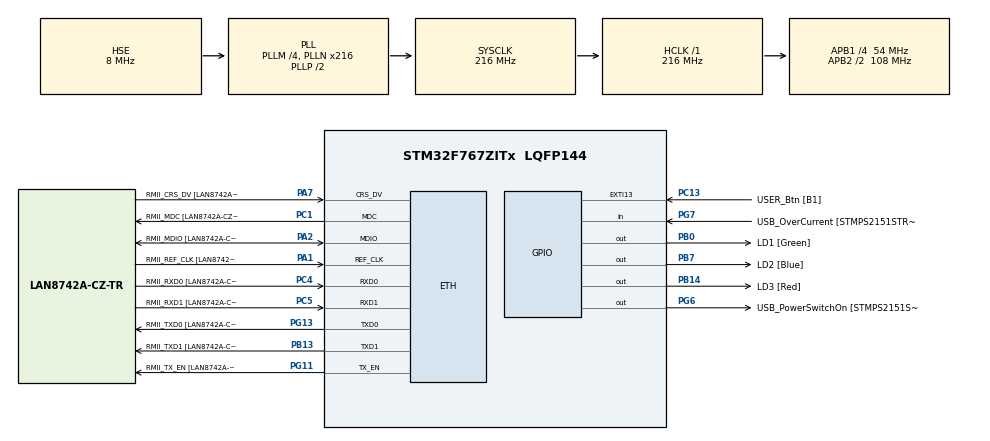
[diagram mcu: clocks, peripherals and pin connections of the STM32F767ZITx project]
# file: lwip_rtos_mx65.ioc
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ETH.MediaInterface=ETH_MEDIA_INTERFACE_RMII
ETH.PHY_Name=LAN8742A_PHY_ADDRESS
ETH.PHY_Value=0
ETH.PhyAddress=0
FREERTOS.Tasks01=defaultTask,24,512,StartDefaultTask,Default,NULL,Dynamic,NULL,NULL;myTask02,8,128,StartTask02,Default,NULL,Dynamic,NULL,NULL
LWIP.DEFAULT_THREAD_STACKSIZE=2048
LWIP.GATEWAY_ADDRESS=192.168.025.001
LWIP.IP_ADDRESS=192.168.025.100
LWIP.LWIP_DHCP=0
LWIP.MEM_SIZE=17000
LWIP.NETMASK_ADDRESS=255.255.255.000
LWIP.TCPIP_THREAD_STACKSIZE=2048
LWIP.Version=v2.1.2_Cube
Mcu.Family=STM32F7
Mcu.Name=STM32F767ZITx
Mcu.Package=LQFP144
NVIC.ETH_IRQn=true\:5\:0\:false\:false\:true\:true\:false\:true\:true
NVIC.PriorityGroup=NVIC_PRIORITYGROUP_4
NVIC.TIM1_BRK_TIM9_IRQn=true\:15\:0\:false\:false\:true\:false\:false\:true\:true
NVIC.TimeBase=TIM1_BRK_TIM9_IRQn
NVIC.TimeBaseIP=TIM9
PA1.GPIO_Label=RMII_REF_CLK [LAN8742A-CZ-TR_REFCLK0]
PA1.Mode=RMII
PA1.Signal=ETH_REF_CLK
PA13.GPIO_Label=TMS
PA13.Mode=Serial_Wire
PA13.Signal=SYS_JTMS-SWDIO
PA14.GPIO_Label=TCK
PA14.Mode=Serial_Wire
PA14.Signal=SYS_JTCK-SWCLK
PA2.GPIO_Label=RMII_MDIO [LAN8742A-CZ-TR_MDIO]
PA2.Mode=RMII
PA2.Signal=ETH_MDIO
PA7.GPIO_Label=RMII_CRS_DV [LAN8742A-CZ-TR_CRS_DV]
PA7.Mode=RMII
PA7.Signal=ETH_CRS_DV
PB0.GPIO_Label=LD1 [Green]
PB0.Signal=GPIO_Output
PB13.GPIO_Label=RMII_TXD1 [LAN8742A-CZ-TR_TXD1]
PB13.Mode=RMII
PB13.Signal=ETH_TXD1
PB14.GPIO_Label=LD3 [Red]
PB14.Signal=GPIO_Output
PB3.GPIO_Label=SWO
PB3.Signal=SYS_JTDO-SWO
PB7.GPIO_Label=LD2 [Blue]
PB7.Signal=GPIO_Output
PC1.GPIO_Label=RMII_MDC [LAN8742A-CZ-TR_MDC]
PC1.Mode=RMII
PC1.Signal=ETH_MDC
PC13.GPIO_Label=USER_Btn [B1]
PC13.Signal=GPXTI13
PC4.GPIO_Label=RMII_RXD0 [LAN8742A-CZ-TR_RXD0]
PC4.Mode=RMII
PC4.Signal=ETH_RXD0
PC5.GPIO_Label=RMII_RXD1 [LAN8742A-CZ-TR_RXD1]
PC5.Mode=RMII
PC5.Signal=ETH_RXD1
PG11.GPIO_Label=RMII_TX_EN [LAN8742A-CZ-TR_TXEN]
PG11.Mode=RMII
PG11.Signal=ETH_TX_EN
PG13.GPIO_Label=RMII_TXD0 [LAN8742A-CZ-TR_TXD0]
PG13.Mode=RMII
PG13.Signal=ETH_TXD0
PG6.GPIO_Label=USB_PowerSwitchOn [STMPS2151STR_EN]
PG6.Signal=GPIO_Output
PG7.GPIO_Label=USB_OverCurrent [STMPS2151STR_FAULT]
PG7.Signal=GPIO_Input
PH0/OSC_IN.GPIO_Label=MCO [STM32F103CBT6_PA8]
PH0/OSC_IN.Mode=HSE-External-Clock-Source
PH0/OSC_IN.Signal=RCC_OSC_IN
PH1/OSC_OUT.Mode=HSE-External-Clock-Source
PH1/OSC_OUT.Signal=RCC_OSC_OUT
ProjectManager.HeapSize=0x200
ProjectManager.StackSize=0x400
ProjectManager.TargetToolchain=STM32CubeIDE
RCC.48MHZClocksFreq_Value=24000000
RCC.AHBFreq_Value=216000000
RCC.APB1CLKDivider=RCC_HCLK_DIV4
RCC.APB1Freq_Value=54000000
RCC.APB1TimFreq_Value=108000000
RCC.APB2CLKDivider=RCC_HCLK_DIV2
RCC.APB2Freq_Value=108000000
RCC.APB2TimFreq_Value=216000000
RCC.CortexFreq_Value=216000000
RCC.HCLKFreq_Value=216000000
RCC.HSE_VALUE=8000000
RCC.HSI_VALUE=16000000
RCC.LSE_VALUE=32768
RCC.PLLM=4
RCC.PLLMUL=RCC_PLL_MUL9
RCC.PLLN=216
RCC.PLLQ=9
RCC.PLLSourceVirtual=RCC_PLLSOURCE_HSE
RCC.PRESCALERUSB=RCC_USBCLKSOURCE_PLL_DIV1_5
RCC.SYSCLKFreq_VALUE=216000000
RCC.SYSCLKSource=RCC_SYSCLKSOURCE_PLLCLK
RCC.SYSCLKSourceVirtual=RCC_SYSCLKSOURCE_PLLCLK
RCC.USBFreq_Value=48000000
RCC.VCOOutputFreq_Value=432000000
VP_FREERTOS_VS_CMSIS_V2.Mode=CMSIS_V2
VP_LWIP_VS_Enabled.Mode=Enabled
VP_SYS_VS_tim9.Mode=TIM9
board=NUCLEO-F767ZI

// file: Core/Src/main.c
/* USER CODE BEGIN Header */
/**
  ******************************************************************************
  * @file           : main.c
  * @brief          : Main program body
  ******************************************************************************
  * @attention
  *
  * Copyright (c) 2025 STMicroelectronics.
  * All rights reserved.
  *
  * This software is licensed under terms that can be found in the LICENSE file
  * in the root directory of this software component.
  * If no LICENSE file comes with this software, it is provided AS-IS.
  *
  ******************************************************************************
  */
/* USER CODE END Header */
#include "main.h"
#include "cmsis_os.h"
#include "lwip.h"
#include "gpio.h"

void SystemClock_Config(void);
void MX_FREERTOS_Init(void);

int main(void)
{

  /* MCU Configuration--------------------------------------------------------*/

  /* Reset of all peripherals, Initializes the Flash interface and the Systick. */
  HAL_Init();

  /* Configure the system clock */
  SystemClock_Config();

  /* Initialize all configured peripherals */
  MX_GPIO_Init();

  /* Init scheduler */
  osKernelInitialize();  /* Call init function for freertos objects (in freertos.c) */
  MX_FREERTOS_Init();

  /* Start scheduler */
  osKernelStart();

  /* We should never get here as control is now taken by the scheduler */
  /* Infinite loop */
  while (1)
  {

  }
}

void SystemClock_Config(void)
{
  RCC_OscInitTypeDef RCC_OscInitStruct = {0};
  RCC_ClkInitTypeDef RCC_ClkInitStruct = {0};

  /** Configure the main internal regulator output voltage
  */
  __HAL_RCC_PWR_CLK_ENABLE();
  __HAL_PWR_VOLTAGESCALING_CONFIG(PWR_REGULATOR_VOLTAGE_SCALE1);

  /** Initializes the RCC Oscillators according to the specified parameters
  * in the RCC_OscInitTypeDef structure.
  */
  RCC_OscInitStruct.OscillatorType = RCC_OSCILLATORTYPE_HSE;
  RCC_OscInitStruct.HSEState = RCC_HSE_BYPASS;
  RCC_OscInitStruct.PLL.PLLState = RCC_PLL_ON;
  RCC_OscInitStruct.PLL.PLLSource = RCC_PLLSOURCE_HSE;
  RCC_OscInitStruct.PLL.PLLM = 4;
  RCC_OscInitStruct.PLL.PLLN = 216;
  RCC_OscInitStruct.PLL.PLLP = RCC_PLLP_DIV2;
  RCC_OscInitStruct.PLL.PLLQ = 9;
  RCC_OscInitStruct.PLL.PLLR = 2;
  if (HAL_RCC_OscConfig(&RCC_OscInitStruct) != HAL_OK)
  {
    Error_Handler();
  }

  /** Activate the Over-Drive mode
  */
  if (HAL_PWREx_EnableOverDrive() != HAL_OK)
  {
    Error_Handler();
  }

  /** Initializes the CPU, AHB and APB buses clocks
  */
  RCC_ClkInitStruct.ClockType = RCC_CLOCKTYPE_HCLK|RCC_CLOCKTYPE_SYSCLK
                              |RCC_CLOCKTYPE_PCLK1|RCC_CLOCKTYPE_PCLK2;
  RCC_ClkInitStruct.SYSCLKSource = RCC_SYSCLKSOURCE_PLLCLK;
  RCC_ClkInitStruct.AHBCLKDivider = RCC_SYSCLK_DIV1;
  RCC_ClkInitStruct.APB1CLKDivider = RCC_HCLK_DIV4;
  RCC_ClkInitStruct.APB2CLKDivider = RCC_HCLK_DIV2;

  if (HAL_RCC_ClockConfig(&RCC_ClkInitStruct, FLASH_LATENCY_7) != HAL_OK)
  {
    Error_Handler();
  }
}

void HAL_TIM_PeriodElapsedCallback(TIM_HandleTypeDef *htim)
{
  if (htim->Instance == TIM9) {
    HAL_IncTick();
  }
}

void Error_Handler(void)
{
  __disable_irq();
  while (1)
  {
  }
}

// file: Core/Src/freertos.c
/* USER CODE BEGIN Header */
/**
  ******************************************************************************
  * File Name          : freertos.c
  * Description        : Code for freertos applications
  ******************************************************************************
  * @attention
  *
  * Copyright (c) 2025 STMicroelectronics.
  * All rights reserved.
  *
  * This software is licensed under terms that can be found in the LICENSE file
  * in the root directory of this software component.
  * If no LICENSE file comes with this software, it is provided AS-IS.
  *
  ******************************************************************************
  */
/* USER CODE END Header */

#include "FreeRTOS.h"
#include "task.h"
#include "main.h"
#include "cmsis_os.h"

/* Definitions for defaultTask */
osThreadId_t defaultTaskHandle;
const osThreadAttr_t defaultTask_attributes = {
  .name = "defaultTask",
  .stack_size = 512 * 4,
  .priority = (osPriority_t) osPriorityNormal,
};
/* Definitions for myTask02 */
osThreadId_t myTask02Handle;
const osThreadAttr_t myTask02_attributes = {
  .name = "myTask02",
  .stack_size = 128 * 4,
  .priority = (osPriority_t) osPriorityLow,
};

void StartDefaultTask(void *argument);
void StartTask02(void *argument);

extern void MX_LWIP_Init(void);
void MX_FREERTOS_Init(void); /* (MISRA C 2004 rule 8.1) */

void MX_FREERTOS_Init(void) {

  /* Create the thread(s) */
  /* creation of defaultTask */
  defaultTaskHandle = osThreadNew(StartDefaultTask, NULL, &defaultTask_attributes);

  /* creation of myTask02 */
  myTask02Handle = osThreadNew(StartTask02, NULL, &myTask02_attributes);

}

void StartDefaultTask(void *argument)
{
  /* init code for LWIP */
  MX_LWIP_Init();
  for(;;)
  {
    osDelay(1);
  }
}

void StartTask02(void *argument)
{
  /* USER CODE BEGIN StartTask02 */
  /* Infinite loop */
  for(;;)
  {
	HAL_GPIO_TogglePin(GPIOB, LD1_Pin);
    osDelay(100);
  }
  /* USER CODE END StartTask02 */
}
